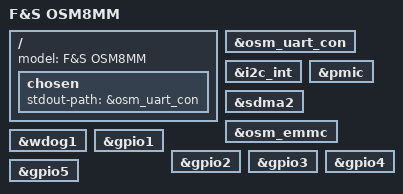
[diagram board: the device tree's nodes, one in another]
/*
 * Copyright (C) 2026 F&S Elektronik Systeme GmbH
 *
 * This program is free software; you can redistribute it and/or modify
 * it under the terms of the GNU General Public License version 2 as
 * published by the Free Software Foundation.
 */

/dts-v1/;

#include "fsimx8mm.dtsi"
#include "osm8mm.dtsi"

/ {
	model = "F&S OSM8MM";

	chosen {
		stdout-path = &osm_uart_con;
	};
};

&osm_uart_con { status = "okay"; };

&i2c_int { status = "okay"; };

&pmic { status = "okay"; };

&sdma2 { status = "okay"; };

&osm_emmc { status = "okay"; };

&wdog1 { status = "okay"; };

&gpio1 { status = "okay"; };
&gpio2 { status = "okay"; };
&gpio3 { status = "okay"; };
&gpio4 { status = "okay"; };
&gpio5 { status = "okay"; };

